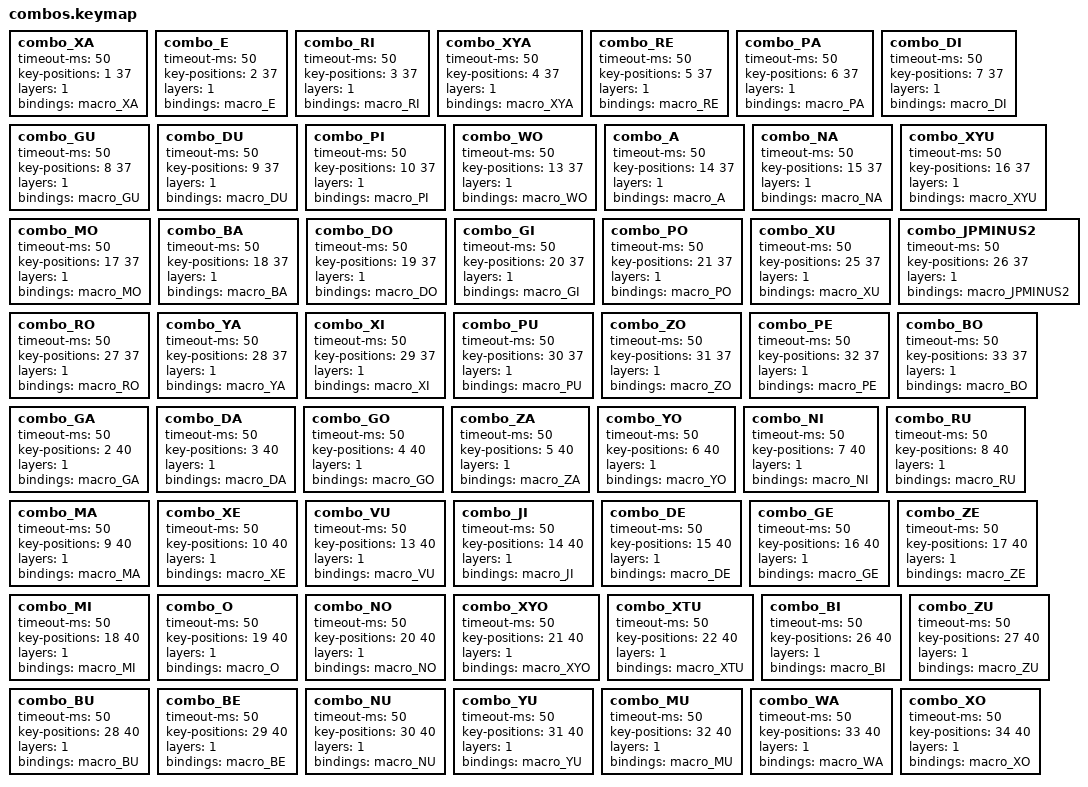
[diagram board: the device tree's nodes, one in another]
        combo_XA {
                timeout-ms = <50>;
                key-positions = <1 37>;
                layers = <1>;
                bindings = <&macro_XA>;
        };

        combo_E {
                timeout-ms = <50>;
                key-positions = <2 37>;
                layers = <1>;
                bindings = <&macro_E>;
        };

        combo_RI {
                timeout-ms = <50>;
                key-positions = <3 37>;
                layers = <1>;
                bindings = <&macro_RI>;
        };

        combo_XYA {
                timeout-ms = <50>;
                key-positions = <4 37>;
                layers = <1>;
                bindings = <&macro_XYA>;
        };

        combo_RE {
                timeout-ms = <50>;
                key-positions = <5 37>;
                layers = <1>;
                bindings = <&macro_RE>;
        };

        combo_PA {
                timeout-ms = <50>;
                key-positions = <6 37>;
                layers = <1>;
                bindings = <&macro_PA>;
        };

        combo_DI {
                timeout-ms = <50>;
                key-positions = <7 37>;
                layers = <1>;
                bindings = <&macro_DI>;
        };

        combo_GU {
                timeout-ms = <50>;
                key-positions = <8 37>;
                layers = <1>;
                bindings = <&macro_GU>;
        };

        combo_DU {
                timeout-ms = <50>;
                key-positions = <9 37>;
                layers = <1>;
                bindings = <&macro_DU>;
        };

        combo_PI {
                timeout-ms = <50>;
                key-positions = <10 37>;
                layers = <1>;
                bindings = <&macro_PI>;
        };

        combo_WO {
                timeout-ms = <50>;
                key-positions = <13 37>;
                layers = <1>;
                bindings = <&macro_WO>;
        };

        combo_A {
                timeout-ms = <50>;
                key-positions = <14 37>;
                layers = <1>;
                bindings = <&macro_A>;
        };

        combo_NA {
                timeout-ms = <50>;
                key-positions = <15 37>;
                layers = <1>;
                bindings = <&macro_NA>;
        };

        combo_XYU {
                timeout-ms = <50>;
                key-positions = <16 37>;
                layers = <1>;
                bindings = <&macro_XYU>;
        };

        combo_MO {
                timeout-ms = <50>;
                key-positions = <17 37>;
                layers = <1>;
                bindings = <&macro_MO>;
        };

        combo_BA {
                timeout-ms = <50>;
                key-positions = <18 37>;
                layers = <1>;
                bindings = <&macro_BA>;
        };

        combo_DO {
                timeout-ms = <50>;
                key-positions = <19 37>;
                layers = <1>;
                bindings = <&macro_DO>;
        };

        combo_GI {
                timeout-ms = <50>;
                key-positions = <20 37>;
                layers = <1>;
                bindings = <&macro_GI>;
        };

        combo_PO {
                timeout-ms = <50>;
                key-positions = <21 37>;
                layers = <1>;
                bindings = <&macro_PO>;
        };

        combo_XU {
                timeout-ms = <50>;
                key-positions = <25 37>;
                layers = <1>;
                bindings = <&macro_XU>;
        };

        combo_JPMINUS2 {
                timeout-ms = <50>;
                key-positions = <26 37>;
                layers = <1>;
                bindings = <&macro_JPMINUS2>;
        };

        combo_RO {
                timeout-ms = <50>;
                key-positions = <27 37>;
                layers = <1>;
                bindings = <&macro_RO>;
        };

        combo_YA {
                timeout-ms = <50>;
                key-positions = <28 37>;
                layers = <1>;
                bindings = <&macro_YA>;
        };

        combo_XI {
                timeout-ms = <50>;
                key-positions = <29 37>;
                layers = <1>;
                bindings = <&macro_XI>;
        };

        combo_PU {
                timeout-ms = <50>;
                key-positions = <30 37>;
                layers = <1>;
                bindings = <&macro_PU>;
        };

        combo_ZO {
                timeout-ms = <50>;
                key-positions = <31 37>;
                layers = <1>;
                bindings = <&macro_ZO>;
        };

        combo_PE {
                timeout-ms = <50>;
                key-positions = <32 37>;
                layers = <1>;
                bindings = <&macro_PE>;
        };

        combo_BO {
                timeout-ms = <50>;
                key-positions = <33 37>;
                layers = <1>;
                bindings = <&macro_BO>;
        };

        combo_GA {
                timeout-ms = <50>;
                key-positions = <2 40>;
                layers = <1>;
                bindings = <&macro_GA>;
        };

        combo_DA {
                timeout-ms = <50>;
                key-positions = <3 40>;
                layers = <1>;
                bindings = <&macro_DA>;
        };

        combo_GO {
                timeout-ms = <50>;
                key-positions = <4 40>;
                layers = <1>;
                bindings = <&macro_GO>;
        };

        combo_ZA {
                timeout-ms = <50>;
                key-positions = <5 40>;
                layers = <1>;
                bindings = <&macro_ZA>;
        };

        combo_YO {
                timeout-ms = <50>;
                key-positions = <6 40>;
                layers = <1>;
                bindings = <&macro_YO>;
        };

        combo_NI {
                timeout-ms = <50>;
                key-positions = <7 40>;
                layers = <1>;
                bindings = <&macro_NI>;
        };

        combo_RU {
                timeout-ms = <50>;
                key-positions = <8 40>;
                layers = <1>;
                bindings = <&macro_RU>;
        };

        combo_MA {
                timeout-ms = <50>;
                key-positions = <9 40>;
                layers = <1>;
                bindings = <&macro_MA>;
        };

        combo_XE {
                timeout-ms = <50>;
                key-positions = <10 40>;
                layers = <1>;
                bindings = <&macro_XE>;
        };

        combo_VU {
                timeout-ms = <50>;
                key-positions = <13 40>;
                layers = <1>;
                bindings = <&macro_VU>;
        };

        combo_JI {
                timeout-ms = <50>;
                key-positions = <14 40>;
                layers = <1>;
                bindings = <&macro_JI>;
        };

        combo_DE {
                timeout-ms = <50>;
                key-positions = <15 40>;
                layers = <1>;
                bindings = <&macro_DE>;
        };

        combo_GE {
                timeout-ms = <50>;
                key-positions = <16 40>;
                layers = <1>;
                bindings = <&macro_GE>;
        };

        combo_ZE {
                timeout-ms = <50>;
                key-positions = <17 40>;
                layers = <1>;
                bindings = <&macro_ZE>;
        };

        combo_MI {
                timeout-ms = <50>;
                key-positions = <18 40>;
                layers = <1>;
                bindings = <&macro_MI>;
        };

        combo_O {
                timeout-ms = <50>;
                key-positions = <19 40>;
                layers = <1>;
                bindings = <&macro_O>;
        };

        combo_NO {
                timeout-ms = <50>;
                key-positions = <20 40>;
                layers = <1>;
                bindings = <&macro_NO>;
        };

        combo_XYO {
                timeout-ms = <50>;
                key-positions = <21 40>;
                layers = <1>;
                bindings = <&macro_XYO>;
        };

        combo_XTU {
                timeout-ms = <50>;
                key-positions = <22 40>;
                layers = <1>;
                bindings = <&macro_XTU>;
        };

        combo_BI {
                timeout-ms = <50>;
                key-positions = <26 40>;
                layers = <1>;
                bindings = <&macro_BI>;
        };

        combo_ZU {
                timeout-ms = <50>;
                key-positions = <27 40>;
                layers = <1>;
                bindings = <&macro_ZU>;
        };

        combo_BU {
                timeout-ms = <50>;
                key-positions = <28 40>;
                layers = <1>;
                bindings = <&macro_BU>;
        };

        combo_BE {
                timeout-ms = <50>;
                key-positions = <29 40>;
                layers = <1>;
                bindings = <&macro_BE>;
        };

        combo_NU {
                timeout-ms = <50>;
                key-positions = <30 40>;
                layers = <1>;
                bindings = <&macro_NU>;
        };

        combo_YU {
                timeout-ms = <50>;
                key-positions = <31 40>;
                layers = <1>;
                bindings = <&macro_YU>;
        };

        combo_MU {
                timeout-ms = <50>;
                key-positions = <32 40>;
                layers = <1>;
                bindings = <&macro_MU>;
        };

        combo_WA {
                timeout-ms = <50>;
                key-positions = <33 40>;
                layers = <1>;
                bindings = <&macro_WA>;
        };

        combo_XO {
                timeout-ms = <50>;
                key-positions = <34 40>;
                layers = <1>;
                bindings = <&macro_XO>;
        };
